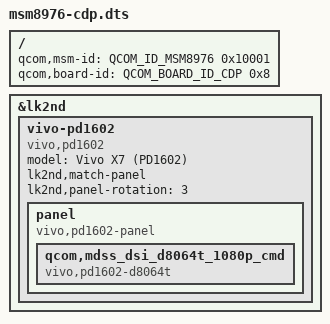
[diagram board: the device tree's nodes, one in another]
// SPDX-License-Identifier: BSD-3-Clause

#include <skeleton64.dtsi>
#include <lk2nd.dtsi>

/ {
	qcom,msm-id = <QCOM_ID_MSM8976 0x10001>;
	qcom,board-id = <QCOM_BOARD_ID_CDP 0x8>;
};

&lk2nd {
	vivo-pd1602 {
		model = "Vivo X7 (PD1602)";
		compatible = "vivo,pd1602";
		lk2nd,match-panel;
		lk2nd,panel-rotation = <3>;

		panel {
			compatible = "vivo,pd1602-panel", "lk2nd,panel";

			qcom,mdss_dsi_d8064t_1080p_cmd {
				compatible = "vivo,pd1602-d8064t";
			};
		};
	};
};
